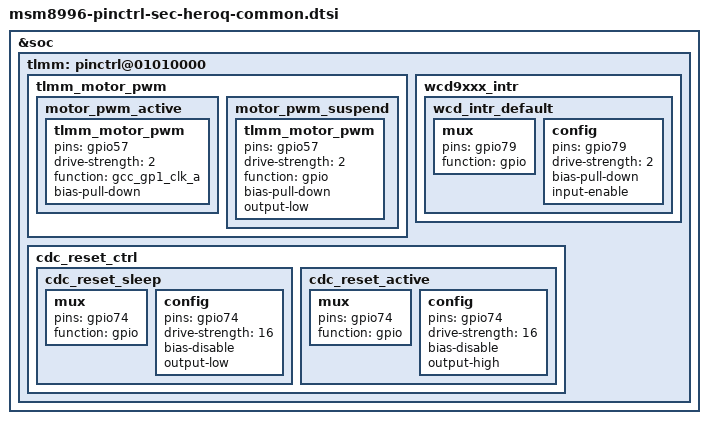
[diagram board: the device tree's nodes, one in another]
/* Copyright (c) 2014-2015, The Linux Foundation. All rights reserved.
 *
 * This program is free software; you can redistribute it and/or modify
 * it under the terms of the GNU General Public License version 2 and
 * only version 2 as published by the Free Software Foundation.
 *
 * This program is distributed in the hope that it will be useful,
 * but WITHOUT ANY WARRANTY; without even the implied warranty of
 * MERCHANTABILITY or FITNESS FOR A PARTICULAR PURPOSE.  See the
 * GNU General Public License for more details.
 */


&soc {
	tlmm: pinctrl@01010000 {
		/delete-node/ pmx_rd_nfc_int;
		/delete-node/ i2c_6;

		/* add pinctrl for motor  */
		tlmm_motor_pwm {
			motor_pwm_active: motor_pwm_active {
				tlmm_motor_pwm {
					pins = "gpio57";
					drive-strength = <2>;
					function = "gcc_gp1_clk_a";
					bias-pull-down; /* PULL DOWN */
				};
			};
			motor_pwm_suspend: motor_pwm_suspend {
				tlmm_motor_pwm {
					pins = "gpio57";
					drive-strength = <2>;
					function = "gpio";
					bias-pull-down; /* PULL DOWN */
					output-low;
				};
			};
		};

		/delete-node/ wcd9xxx_intr;
		wcd9xxx_intr {
			wcd_intr_default: wcd_intr_default{
				mux {
					pins = "gpio79";
					function = "gpio";
				};

				config {
					pins = "gpio79";
					drive-strength = <2>; /* 2 mA */
					bias-pull-down; /* pull down */
					input-enable;
				};
			};
		};

		/delete-node/ cdc_reset_ctrl;
		cdc_reset_ctrl {
			cdc_reset_sleep: cdc_reset_sleep {
				mux {
					pins = "gpio74";
					function = "gpio";
				};
				config {
					pins = "gpio74";
					drive-strength = <16>;
					bias-disable;
					output-low;
				};
			};
			cdc_reset_active:cdc_reset_active {
				mux {
					pins = "gpio74";
					function = "gpio";
				};
				config {
					pins = "gpio74";
					drive-strength = <16>;
					bias-disable;
					output-high;
				};
			};
		};
	};
};
